AUTOSAR XML (schema 00049)
package /AdaptiveApplicationSwComponentTypes
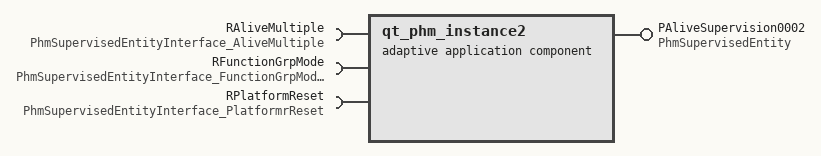
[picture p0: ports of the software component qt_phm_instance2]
  adaptive application sw component type qt_phm_instance2: category=APPLICATION_LEVEL
    provide port PAliveSupervision0002: provided-interface=PhmSupervisedEntity
    require port RAliveMultiple: required-interface=PhmSupervisedEntityInterface_AliveMultiple
    require port RFunctionGrpMode: required-interface=PhmSupervisedEntityInterface_FunctionGrpModeRequest
    require port RPlatformReset: required-interface=PhmSupervisedEntityInterface_PlatformrReset
package /Executables
  executable qt_phm_instance2
    root sw component prototype rootSwComponentPrototype2: application-type=qt_phm_instance2
package /ProcessDesign
  process design qt_phm_instance2: executable=qt_phm_instance2
